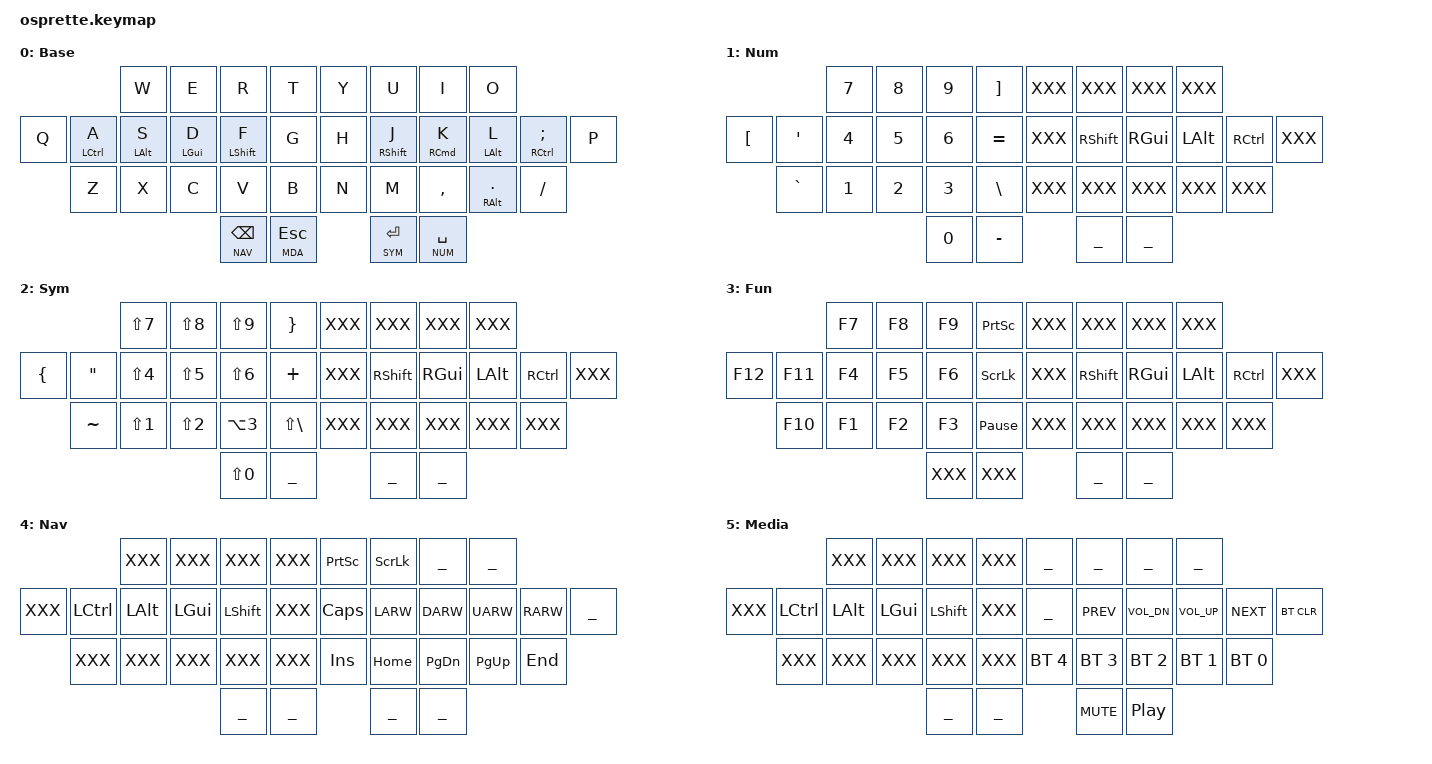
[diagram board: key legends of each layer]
/*
 * Copyright (c) 2021 Pete Johanson
 *
 * SPDX-License-Identifier: MIT
 */

#include <behaviors.dtsi>
#include <dt-bindings/zmk/keys.h>
#include <dt-bindings/zmk/bt.h>
#include <dt-bindings/zmk/outputs.h>
#include "3X-key.h"

// Using layer taps on thumbs, having quick tap as well helps w/ repeating space/backspace
// &lt { quick_tap_ms = <200>; };

/ {
    kscan0 {
        debounce-press-ms = <25>;
    };

    combos {
        #include "osprette_combos.dtsi"

        del_t {
	    timeout-ms = <70>;
            key-positions = <30 31>;
            bindings = <&kp DEL>;
        };

        fn_lt {
	    timeout-ms = <70>;
            key-positions = <32 33>;
            bindings = <&lt FUNC TAB>;
        };

    };

    behaviors {
        #include "behaviors.dtsi"
    };

    keymap {
        compatible = "zmk,keymap";

        default_layer {
            label = "Base";
            bindings = <
                            &kp W      &kp E      &kp R       &kp T   &kp Y  &kp U       &kp I      &kp O
          &kp Q &hm LCTRL A &hm LALT S &hm LGUI D &hm LSHFT F &kp G   &kp H  &hm RSHFT J &hm RCMD K &hm LALT L   &hm RCTRL SEMI &kp P
                &kp Z       &kp X      &kp C      &kp V       &kp B   &kp N  &kp M       &kp COMMA  &hm RALT DOT &kp FSLH
                                                  &lt NAV BKSP &lt MDA ESC &lt SYM RET &lt NUM SPACE
            >;
        };

        num_layer {
            label = "Num";
            bindings = <
                          &kp N7 &kp N8 &kp N9 &kp RBKT   XXX XXX       XXX      XXX
       &kp LBKT &kp QUOT  &kp N4 &kp N5 &kp N6 &kp EQUAL  XXX &kp RSHFT &kp RGUI &kp LALT &kp RCTL XXX
                &kp GRAVE &kp N1 &kp N2 &kp N3 &kp BSLH   XXX XXX       XXX      XXX      XXX
                                        &kp N0 &kp MINUS  ___ ___
            >;
        };

        sym_layer {
            label = "Sym";
            bindings = <
                          &kp LS(N7) &kp LS(N8) &kp LS(N9) &kp RBRC      XXX XXX       XXX      XXX
       &kp LBRC &kp DQT   &kp LS(N4) &kp LS(N5) &kp LS(N6) &kp PLUS      XXX &kp RSHFT &kp RGUI &kp LALT &kp RCTL XXX
                &kp TILDE &kp LS(N1) &kp LS(N2) &kp LA(N3) &kp LS(BSLH)  XXX XXX       XXX      XXX      XXX
                                                &kp LS(N0) &kp UNDER     ___ ___
            >;
        };

        fun_layer {
            label = "Fun";
            bindings = <
                        &kp F7 &kp F8 &kp F9 &kp PSCRN        XXX XXX       XXX      XXX
        &kp F12 &kp F11 &kp F4 &kp F5 &kp F6 &kp SLCK         XXX &kp RSHFT &kp RGUI &kp LALT &kp RCTL XXX
                &kp F10 &kp F1 &kp F2 &kp F3 &kp PAUSE_BREAK  XXX XXX       XXX      XXX      XXX
                                      XXX    XXX              ___ ___
            >;
        };

        nav_layer {
            label = "Nav";
            bindings = <
                         XXX      XXX      XXX       XXX  &kp PSCRN &kp SLCK ___        ___
            XXX &kp LCTL &kp LALT &kp LGUI &kp LSHFT XXX  &kp CAPS  &kp LARW &kp DARW   &kp UARW  &kp RARW ___
                XXX      XXX      XXX      XXX       XXX  &kp INS   &kp HOME &kp PG_DN  &kp PG_UP &kp END
                                           ___       ___  ___       ___
            >;
        };

        media_layer {
            label = "Media";
            bindings = <
                         XXX      XXX      XXX       XXX  ___          ___            ___          ___
            XXX &kp LCTL &kp LALT &kp LGUI &kp LSHFT XXX  ___          &kp C_PREV     &kp C_VOL_DN &kp C_VOL_UP &kp C_NEXT &bt BT_CLR
                XXX      XXX      XXX      XXX       XXX  &bt BT_SEL 4 &bt BT_SEL 3   &bt BT_SEL 2 &bt BT_SEL 1 &bt BT_SEL 0
                                           ___       ___  &kp C_MUTE   &kp C_PLAY_PAUSE
            >;
        };
    };
};

